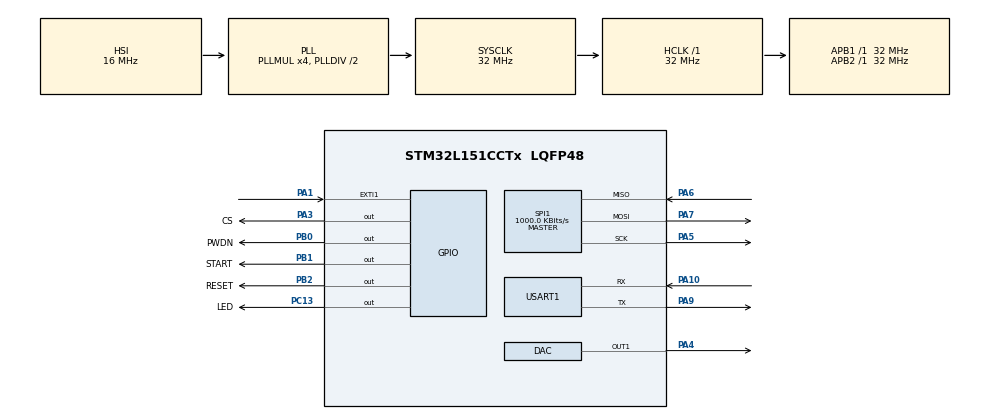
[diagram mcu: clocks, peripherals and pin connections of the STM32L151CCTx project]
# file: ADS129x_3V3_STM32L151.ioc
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Mcu.Family=STM32L1
Mcu.Name=STM32L151CCTx
Mcu.Package=LQFP48
NVIC.EXTI1_IRQn=true\:0\:0\:false\:false\:true\:true
NVIC.PriorityGroup=NVIC_PRIORITYGROUP_4
PA1.Signal=GPXTI1
PA10.Mode=Asynchronous
PA10.Signal=USART1_RX
PA3.GPIO_Label=CS
PA3.GPIO_Speed=GPIO_SPEED_FREQ_MEDIUM
PA3.Signal=GPIO_Output
PA4.Signal=COMP_DAC1_group
PA5.GPIO_PuPd=GPIO_PULLUP
PA5.GPIO_Speed=GPIO_SPEED_FREQ_HIGH
PA5.Mode=Full_Duplex_Master
PA5.Signal=SPI1_SCK
PA6.Mode=Full_Duplex_Master
PA6.Signal=SPI1_MISO
PA7.GPIO_Speed=GPIO_SPEED_FREQ_HIGH
PA7.Mode=Full_Duplex_Master
PA7.Signal=SPI1_MOSI
PA9.Mode=Asynchronous
PA9.Signal=USART1_TX
PB0.GPIO_Label=PWDN
PB0.GPIO_Speed=GPIO_SPEED_FREQ_MEDIUM
PB0.Signal=GPIO_Output
PB1.GPIO_Label=START
PB1.GPIO_Speed=GPIO_SPEED_FREQ_MEDIUM
PB1.Signal=GPIO_Output
PB2.GPIO_Label=RESET
PB2.GPIO_Speed=GPIO_SPEED_FREQ_MEDIUM
PB2.Signal=GPIO_Output
PC13-WKUP2.GPIO_Label=LED
PC13-WKUP2.GPIO_Speed=GPIO_SPEED_FREQ_MEDIUM
PC13-WKUP2.Signal=GPIO_Output
ProjectManager.HeapSize=0x200
ProjectManager.StackSize=0x400
ProjectManager.TargetToolchain=EWARM
RCC.AHBFreq_Value=32000000
RCC.APB1Freq_Value=32000000
RCC.APB1TimFreq_Value=32000000
RCC.APB2Freq_Value=32000000
RCC.APB2TimFreq_Value=32000000
RCC.HCLKFreq_Value=32000000
RCC.HSE_VALUE=24000000
RCC.HSI_VALUE=16000000
RCC.LSE_VALUE=32768
RCC.MSI_VALUE=2097000
RCC.PLLMUL=RCC_PLL_MUL4
RCC.SYSCLKFreq_VALUE=32000000
RCC.SYSCLKSource=RCC_SYSCLKSOURCE_PLLCLK
RCC.USBOutput=32000000
RCC.VCOOutputFreq_Value=64000000
SH.COMP_DAC1_group.0=DAC_OUT1,DAC_OUT1
SPI1.BaudRatePrescaler=SPI_BAUDRATEPRESCALER_32
SPI1.CLKPhase=SPI_PHASE_2EDGE
SPI1.CalculateBaudRate=1000.0 KBits/s
SPI1.Direction=SPI_DIRECTION_2LINES
SPI1.Mode=SPI_MODE_MASTER
SPI1.VirtualType=VM_MASTER
USART1.VirtualMode=VM_ASYNC
board=ADS129x_3V3_STM32L151

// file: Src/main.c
/**
  ******************************************************************************
  * File Name          : main.c
  * Description        : Main program body
  ******************************************************************************
  ** This notice applies to any and all portions of this file
  * that are not between comment pairs USER CODE BEGIN and
  * USER CODE END. Other portions of this file, whether
  * inserted by the user or by software development tools
  * are owned by their respective copyright owners.
  *
  * COPYRIGHT(c) 2018 STMicroelectronics
  *
  * Redistribution and use in source and binary forms, with or without modification,
  * are permitted provided that the following conditions are met:
  *   1. Redistributions of source code must retain the above copyright notice,
  *      this list of conditions and the following disclaimer.
  *   2. Redistributions in binary form must reproduce the above copyright notice,
  *      this list of conditions and the following disclaimer in the documentation
  *      and/or other materials provided with the distribution.
  *   3. Neither the name of STMicroelectronics nor the names of its contributors
  *      may be used to endorse or promote products derived from this software
  *      without specific prior written permission.
  *
  * THIS SOFTWARE IS PROVIDED BY THE COPYRIGHT HOLDERS AND CONTRIBUTORS "AS IS"
  * AND ANY EXPRESS OR IMPLIED WARRANTIES, INCLUDING, BUT NOT LIMITED TO, THE
  * IMPLIED WARRANTIES OF MERCHANTABILITY AND FITNESS FOR A PARTICULAR PURPOSE ARE
  * DISCLAIMED. IN NO EVENT SHALL THE COPYRIGHT HOLDER OR CONTRIBUTORS BE LIABLE
  * FOR ANY DIRECT, INDIRECT, INCIDENTAL, SPECIAL, EXEMPLARY, OR CONSEQUENTIAL
  * DAMAGES (INCLUDING, BUT NOT LIMITED TO, PROCUREMENT OF SUBSTITUTE GOODS OR
  * SERVICES; LOSS OF USE, DATA, OR PROFITS; OR BUSINESS INTERRUPTION) HOWEVER
  * CAUSED AND ON ANY THEORY OF LIABILITY, WHETHER IN CONTRACT, STRICT LIABILITY,
  * OR TORT (INCLUDING NEGLIGENCE OR OTHERWISE) ARISING IN ANY WAY OUT OF THE USE
  * OF THIS SOFTWARE, EVEN IF ADVISED OF THE POSSIBILITY OF SUCH DAMAGE.
  *
  ******************************************************************************
  */
#include "main.h"
#include "stm32l1xx_hal.h"

/* USER CODE BEGIN Includes */
//#include "ADS1294.h"
//#include "ADS129x_Devices.h"
#include "DevicePresenter.h"
#include "string.h"
/* USER CODE END Includes */

DAC_HandleTypeDef hdac;

SPI_HandleTypeDef hspi1;

UART_HandleTypeDef huart1;

/* USER CODE BEGIN PV */
/* Private variables ---------------------------------------------------------*/
StatusLed Led = { .port = LED_GPIO_Port, .pin = LED_Pin };
bool DataReady = false;
/* USER CODE END PV */

void SystemClock_Config(void);
static void MX_GPIO_Init(void);
static void MX_SPI1_Init(void);
static void MX_USART1_UART_Init(void);
static void MX_DAC_Init(void);

/* USER CODE BEGIN PFP */
/* Private function prototypes -----------------------------------------------*/

/* USER CODE END PFP */

int main(void)
{

  /* MCU Configuration----------------------------------------------------------*/

  /* Reset of all peripherals, Initializes the Flash interface and the Systick. */
  HAL_Init();

  /* Configure the system clock */
  SystemClock_Config();

  /* Initialize all configured peripherals */
  MX_GPIO_Init();
  MX_SPI1_Init();
  MX_USART1_UART_Init();
  MX_DAC_Init();

  /* USER CODE BEGIN 2 */

  HAL_NVIC_DisableIRQ(EXTI1_IRQn);
  //Init_ADS1294(&hspi1,&hdac);
  DevicePresenter* device = _DevicePresenter(&Led);
  device->Initialize();

  HAL_NVIC_EnableIRQ(EXTI1_IRQn);

  /* USER CODE END 2 */

  /* Infinite loop */
  /* USER CODE BEGIN WHILE */
  while (1)
  {
    if(DataReady == true)
    {
      device->ReadData(&hspi1, &huart1);
    }
  /* USER CODE END WHILE */

  }

}

/** System Clock Configuration
*/
void SystemClock_Config(void)
{

  RCC_OscInitTypeDef RCC_OscInitStruct;
  RCC_ClkInitTypeDef RCC_ClkInitStruct;

    /**Configure the main internal regulator output voltage
    */
  __HAL_PWR_VOLTAGESCALING_CONFIG(PWR_REGULATOR_VOLTAGE_SCALE1);

    /**Initializes the CPU, AHB and APB busses clocks
    */
  RCC_OscInitStruct.OscillatorType = RCC_OSCILLATORTYPE_HSI;
  RCC_OscInitStruct.HSIState = RCC_HSI_ON;
  RCC_OscInitStruct.HSICalibrationValue = 16;
  RCC_OscInitStruct.PLL.PLLState = RCC_PLL_ON;
  RCC_OscInitStruct.PLL.PLLSource = RCC_PLLSOURCE_HSI;
  RCC_OscInitStruct.PLL.PLLMUL = RCC_PLL_MUL4;
  RCC_OscInitStruct.PLL.PLLDIV = RCC_PLL_DIV2;
  if (HAL_RCC_OscConfig(&RCC_OscInitStruct) != HAL_OK)
  {
    _Error_Handler(__FILE__, __LINE__);
  }

    /**Initializes the CPU, AHB and APB busses clocks
    */
  RCC_ClkInitStruct.ClockType = RCC_CLOCKTYPE_HCLK|RCC_CLOCKTYPE_SYSCLK
                              |RCC_CLOCKTYPE_PCLK1|RCC_CLOCKTYPE_PCLK2;
  RCC_ClkInitStruct.SYSCLKSource = RCC_SYSCLKSOURCE_PLLCLK;
  RCC_ClkInitStruct.AHBCLKDivider = RCC_SYSCLK_DIV1;
  RCC_ClkInitStruct.APB1CLKDivider = RCC_HCLK_DIV1;
  RCC_ClkInitStruct.APB2CLKDivider = RCC_HCLK_DIV1;

  if (HAL_RCC_ClockConfig(&RCC_ClkInitStruct, FLASH_LATENCY_1) != HAL_OK)
  {
    _Error_Handler(__FILE__, __LINE__);
  }

    /**Configure the Systick interrupt time
    */
  HAL_SYSTICK_Config(HAL_RCC_GetHCLKFreq()/1000);

    /**Configure the Systick
    */
  HAL_SYSTICK_CLKSourceConfig(SYSTICK_CLKSOURCE_HCLK);

  /* SysTick_IRQn interrupt configuration */
  HAL_NVIC_SetPriority(SysTick_IRQn, 0, 0);
}

/* DAC init function */
static void MX_DAC_Init(void)
{

  DAC_ChannelConfTypeDef sConfig;

    /**DAC Initialization
    */
  hdac.Instance = DAC;
  if (HAL_DAC_Init(&hdac) != HAL_OK)
  {
    _Error_Handler(__FILE__, __LINE__);
  }

    /**DAC channel OUT1 config
    */
  sConfig.DAC_Trigger = DAC_TRIGGER_NONE;
  sConfig.DAC_OutputBuffer = DAC_OUTPUTBUFFER_ENABLE;
  if (HAL_DAC_ConfigChannel(&hdac, &sConfig, DAC_CHANNEL_1) != HAL_OK)
  {
    _Error_Handler(__FILE__, __LINE__);
  }

}

/* SPI1 init function */
static void MX_SPI1_Init(void)
{

  /* SPI1 parameter configuration*/
  hspi1.Instance = SPI1;
  hspi1.Init.Mode = SPI_MODE_MASTER;
  hspi1.Init.Direction = SPI_DIRECTION_2LINES;
  hspi1.Init.DataSize = SPI_DATASIZE_8BIT;
  hspi1.Init.CLKPolarity = SPI_POLARITY_LOW;
  hspi1.Init.CLKPhase = SPI_PHASE_2EDGE;
  hspi1.Init.NSS = SPI_NSS_SOFT;
  hspi1.Init.BaudRatePrescaler = SPI_BAUDRATEPRESCALER_32;
  hspi1.Init.FirstBit = SPI_FIRSTBIT_MSB;
  hspi1.Init.TIMode = SPI_TIMODE_DISABLE;
  hspi1.Init.CRCCalculation = SPI_CRCCALCULATION_DISABLE;
  hspi1.Init.CRCPolynomial = 10;
  if (HAL_SPI_Init(&hspi1) != HAL_OK)
  {
    _Error_Handler(__FILE__, __LINE__);
  }

}

/* USART1 init function */
static void MX_USART1_UART_Init(void)
{

  huart1.Instance = USART1;
  huart1.Init.BaudRate = 115200;
  huart1.Init.WordLength = UART_WORDLENGTH_8B;
  huart1.Init.StopBits = UART_STOPBITS_1;
  huart1.Init.Parity = UART_PARITY_NONE;
  huart1.Init.Mode = UART_MODE_TX_RX;
  huart1.Init.HwFlowCtl = UART_HWCONTROL_NONE;
  huart1.Init.OverSampling = UART_OVERSAMPLING_16;
  if (HAL_UART_Init(&huart1) != HAL_OK)
  {
    _Error_Handler(__FILE__, __LINE__);
  }

}

/** Configure pins as
        * Analog
        * Input
        * Output
        * EVENT_OUT
        * EXTI
*/
static void MX_GPIO_Init(void)
{

  GPIO_InitTypeDef GPIO_InitStruct;

  /* GPIO Ports Clock Enable */
  __HAL_RCC_GPIOC_CLK_ENABLE();
  __HAL_RCC_GPIOA_CLK_ENABLE();
  __HAL_RCC_GPIOB_CLK_ENABLE();

  /*Configure GPIO pin Output Level */
  HAL_GPIO_WritePin(LED_GPIO_Port, LED_Pin, GPIO_PIN_RESET);

  /*Configure GPIO pin Output Level */
  HAL_GPIO_WritePin(CS_GPIO_Port, CS_Pin, GPIO_PIN_RESET);

  /*Configure GPIO pin Output Level */
  HAL_GPIO_WritePin(GPIOB, PWDN_Pin|START_Pin|RESET_Pin, GPIO_PIN_RESET);

  /*Configure GPIO pin : LED_Pin */
  GPIO_InitStruct.Pin = LED_Pin;
  GPIO_InitStruct.Mode = GPIO_MODE_OUTPUT_PP;
  GPIO_InitStruct.Pull = GPIO_NOPULL;
  GPIO_InitStruct.Speed = GPIO_SPEED_FREQ_MEDIUM;
  HAL_GPIO_Init(LED_GPIO_Port, &GPIO_InitStruct);

  /*Configure GPIO pin : PA1 */
  GPIO_InitStruct.Pin = GPIO_PIN_1;
  GPIO_InitStruct.Mode = GPIO_MODE_IT_RISING;
  GPIO_InitStruct.Pull = GPIO_NOPULL;
  HAL_GPIO_Init(GPIOA, &GPIO_InitStruct);

  /*Configure GPIO pin : CS_Pin */
  GPIO_InitStruct.Pin = CS_Pin;
  GPIO_InitStruct.Mode = GPIO_MODE_OUTPUT_PP;
  GPIO_InitStruct.Pull = GPIO_NOPULL;
  GPIO_InitStruct.Speed = GPIO_SPEED_FREQ_MEDIUM;
  HAL_GPIO_Init(CS_GPIO_Port, &GPIO_InitStruct);

  /*Configure GPIO pins : PWDN_Pin START_Pin RESET_Pin */
  GPIO_InitStruct.Pin = PWDN_Pin|START_Pin|RESET_Pin;
  GPIO_InitStruct.Mode = GPIO_MODE_OUTPUT_PP;
  GPIO_InitStruct.Pull = GPIO_NOPULL;
  GPIO_InitStruct.Speed = GPIO_SPEED_FREQ_MEDIUM;
  HAL_GPIO_Init(GPIOB, &GPIO_InitStruct);

  /* EXTI interrupt init*/
  HAL_NVIC_SetPriority(EXTI1_IRQn, 0, 0);
  HAL_NVIC_EnableIRQ(EXTI1_IRQn);

}

/* USER CODE BEGIN 4 */
void HAL_GPIO_EXTI_Callback(uint16_t GPIO_Pin)
{
  DataReady = true;
}
/* USER CODE END 4 */

void _Error_Handler(char * file, int line)
{
  while(1)
  {
  }
}

/************************ (C) COPYRIGHT STMicroelectronics *****END OF FILE****/
